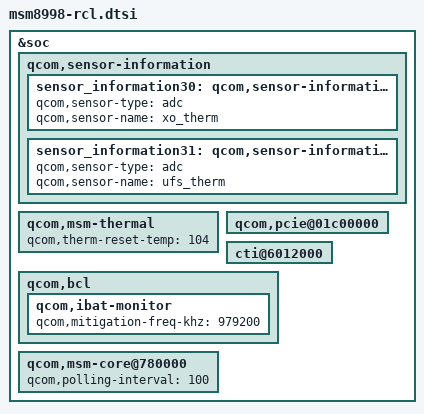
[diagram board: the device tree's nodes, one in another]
/* Copyright (c) 2015-2018, The Linux Foundation. All rights reserved.
 *
 * This program is free software; you can redistribute it and/or modify
 * it under the terms of the GNU General Public License version 2 and
 * only version 2 as published by the Free Software Foundation.
 *
 * This program is distributed in the hope that it will be useful,
 * but WITHOUT ANY WARRANTY; without even the implied warranty of
 * MERCHANTABILITY or FITNESS FOR A PARTICULAR PURPOSE.  See the
 * GNU General Public License for more details.
 */

&soc {
	qcom,sensor-information {
		sensor_information30: qcom,sensor-information-30 {
			qcom,sensor-type = "adc";
			qcom,sensor-name = "xo_therm";
		};
		sensor_information31: qcom,sensor-information-31 {
			qcom,sensor-type = "adc";
			qcom,sensor-name = "ufs_therm";
		};
	};

	qcom,msm-thermal {
		qcom,therm-reset-temp = <104>;
	};

	qcom,pcie@01c00000 {
		/delete-property/ pinctrl-names;
		/delete-property/ pinctrl-0;
		/delete-property/ pinctrl-1;
		/delete-property/ wake-gpio;
	};

	cti@6012000 {
		/delete-property/ pinctrl-names;
		/delete-property/ pinctrl-0;
	};

	qcom,bcl {
		qcom,ibat-monitor {
			qcom,mitigation-freq-khz = <979200>;
		};
	};

	qcom,msm-core@780000 {
		qcom,polling-interval = <100>;
	};
};
